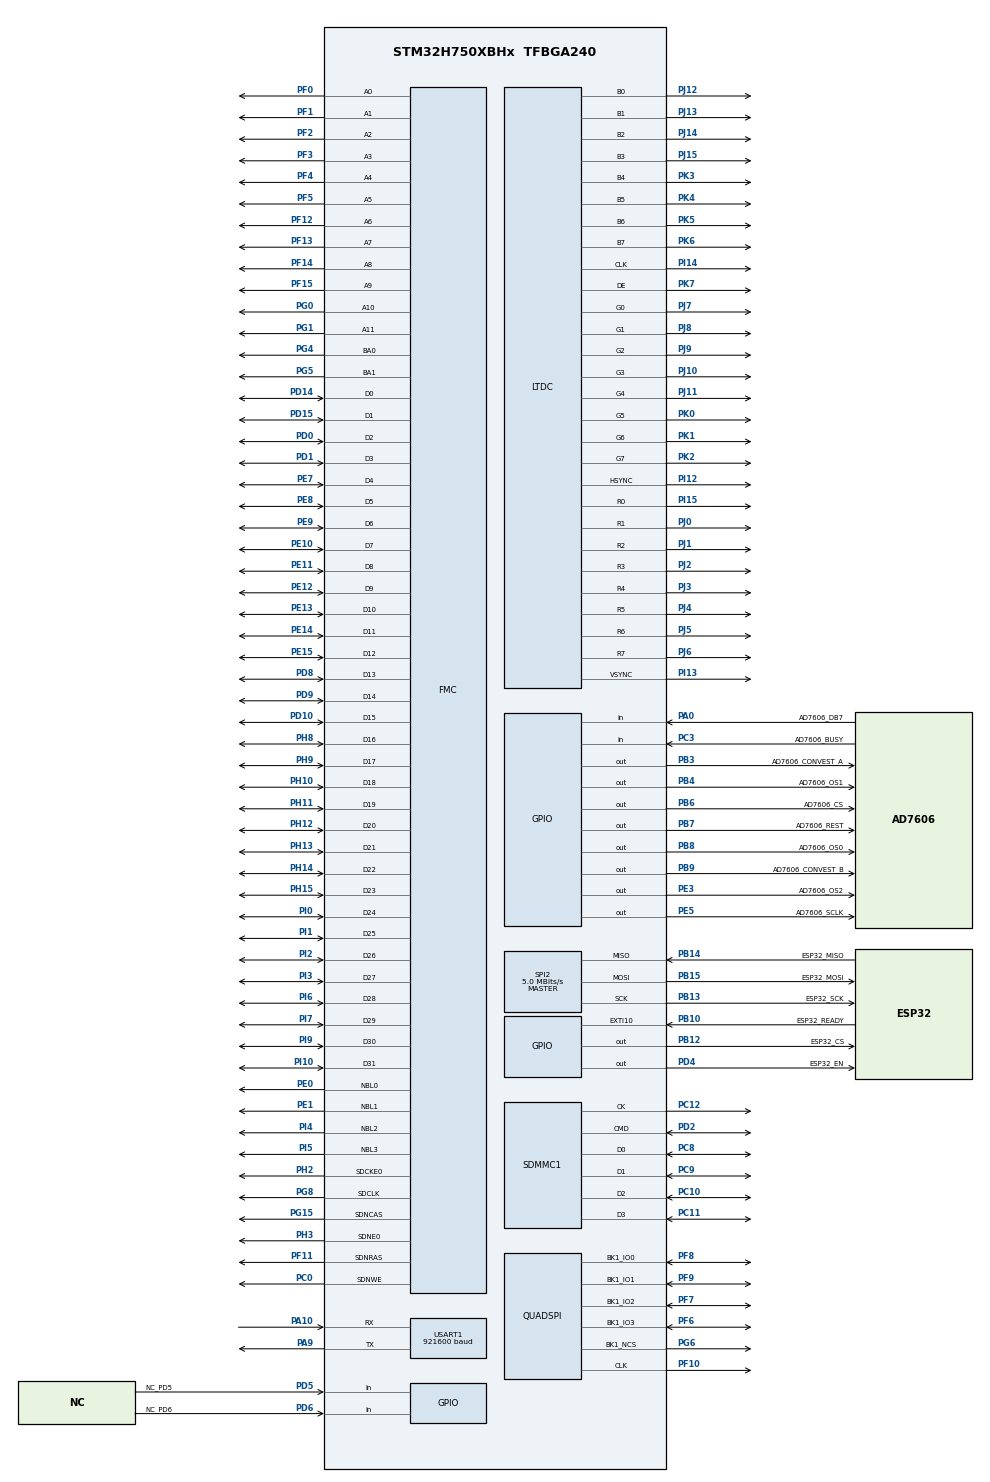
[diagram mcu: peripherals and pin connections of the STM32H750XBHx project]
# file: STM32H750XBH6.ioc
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CORTEX_M7.AccessPermission-Cortex_Memory_Protection_Unit_Region0_Settings=MPU_REGION_FULL_ACCESS
CORTEX_M7.AccessPermission-Cortex_Memory_Protection_Unit_Region1_Settings=MPU_REGION_FULL_ACCESS
CORTEX_M7.BaseAddress-Cortex_Memory_Protection_Unit_Region0_Settings=0xC0000000
CORTEX_M7.BaseAddress-Cortex_Memory_Protection_Unit_Region1_Settings=0x24000000
CORTEX_M7.CPU_DCache=Enabled
CORTEX_M7.CPU_ICache=Enabled
CORTEX_M7.Enable-Cortex_Memory_Protection_Unit_Region0_Settings=MPU_REGION_ENABLE
CORTEX_M7.Enable-Cortex_Memory_Protection_Unit_Region1_Settings=MPU_REGION_ENABLE
CORTEX_M7.IsBufferable-Cortex_Memory_Protection_Unit_Region0_Settings=MPU_ACCESS_NOT_BUFFERABLE
CORTEX_M7.IsBufferable-Cortex_Memory_Protection_Unit_Region1_Settings=MPU_ACCESS_BUFFERABLE
CORTEX_M7.IsCacheable-Cortex_Memory_Protection_Unit_Region0_Settings=MPU_ACCESS_CACHEABLE
CORTEX_M7.IsCacheable-Cortex_Memory_Protection_Unit_Region1_Settings=MPU_ACCESS_CACHEABLE
CORTEX_M7.IsShareable-Cortex_Memory_Protection_Unit_Region1_Settings=MPU_ACCESS_SHAREABLE
CORTEX_M7.MPU_Control=MPU_PRIVILEGED_DEFAULT
CORTEX_M7.Size-Cortex_Memory_Protection_Unit_Region0_Settings=MPU_REGION_SIZE_16MB
CORTEX_M7.Size-Cortex_Memory_Protection_Unit_Region1_Settings=MPU_REGION_SIZE_512KB
CORTEX_M7.TypeExtField-Cortex_Memory_Protection_Unit_Region1_Settings=MPU_TEX_LEVEL1
DMA2D.ColorMode=DMA2D_OUTPUT_RGB565
Dma.Request0=USART1_RX
Dma.Request1=USART1_TX
Dma.Request2=SPI2_RX
Dma.Request3=SPI2_TX
Dma.SPI2_RX.2.Direction=DMA_PERIPH_TO_MEMORY
Dma.SPI2_RX.2.EventEnable=DISABLE
Dma.SPI2_RX.2.FIFOMode=DMA_FIFOMODE_DISABLE
Dma.SPI2_RX.2.Instance=DMA1_Stream4
Dma.SPI2_RX.2.MemDataAlignment=DMA_MDATAALIGN_BYTE
Dma.SPI2_RX.2.MemInc=DMA_MINC_ENABLE
Dma.SPI2_RX.2.Mode=DMA_NORMAL
Dma.SPI2_RX.2.PeriphDataAlignment=DMA_PDATAALIGN_BYTE
Dma.SPI2_RX.2.PeriphInc=DMA_PINC_DISABLE
Dma.SPI2_RX.2.Polarity=HAL_DMAMUX_REQ_GEN_RISING
Dma.SPI2_RX.2.Priority=DMA_PRIORITY_VERY_HIGH
Dma.SPI2_RX.2.RequestNumber=1
Dma.SPI2_RX.2.SignalID=NONE
Dma.SPI2_RX.2.SyncEnable=DISABLE
Dma.SPI2_RX.2.SyncPolarity=HAL_DMAMUX_SYNC_NO_EVENT
Dma.SPI2_RX.2.SyncRequestNumber=1
Dma.SPI2_RX.2.SyncSignalID=NONE
Dma.SPI2_TX.3.Direction=DMA_MEMORY_TO_PERIPH
Dma.SPI2_TX.3.EventEnable=DISABLE
Dma.SPI2_TX.3.FIFOMode=DMA_FIFOMODE_DISABLE
Dma.SPI2_TX.3.Instance=DMA1_Stream5
Dma.SPI2_TX.3.MemDataAlignment=DMA_MDATAALIGN_BYTE
Dma.SPI2_TX.3.MemInc=DMA_MINC_ENABLE
Dma.SPI2_TX.3.Mode=DMA_NORMAL
Dma.SPI2_TX.3.PeriphDataAlignment=DMA_PDATAALIGN_BYTE
Dma.SPI2_TX.3.PeriphInc=DMA_PINC_DISABLE
Dma.SPI2_TX.3.Polarity=HAL_DMAMUX_REQ_GEN_RISING
Dma.SPI2_TX.3.Priority=DMA_PRIORITY_VERY_HIGH
Dma.SPI2_TX.3.RequestNumber=1
Dma.SPI2_TX.3.SignalID=NONE
Dma.SPI2_TX.3.SyncEnable=DISABLE
Dma.SPI2_TX.3.SyncPolarity=HAL_DMAMUX_SYNC_NO_EVENT
Dma.SPI2_TX.3.SyncRequestNumber=1
Dma.SPI2_TX.3.SyncSignalID=NONE
Dma.USART1_RX.0.Direction=DMA_PERIPH_TO_MEMORY
Dma.USART1_RX.0.EventEnable=DISABLE
Dma.USART1_RX.0.FIFOMode=DMA_FIFOMODE_DISABLE
Dma.USART1_RX.0.Instance=DMA1_Stream0
Dma.USART1_RX.0.MemDataAlignment=DMA_MDATAALIGN_BYTE
Dma.USART1_RX.0.MemInc=DMA_MINC_ENABLE
Dma.USART1_RX.0.Mode=DMA_NORMAL
Dma.USART1_RX.0.PeriphDataAlignment=DMA_PDATAALIGN_BYTE
Dma.USART1_RX.0.PeriphInc=DMA_PINC_DISABLE
Dma.USART1_RX.0.Polarity=HAL_DMAMUX_REQ_GEN_RISING
Dma.USART1_RX.0.Priority=DMA_PRIORITY_VERY_HIGH
Dma.USART1_RX.0.RequestNumber=1
Dma.USART1_RX.0.SignalID=NONE
Dma.USART1_RX.0.SyncEnable=DISABLE
Dma.USART1_RX.0.SyncPolarity=HAL_DMAMUX_SYNC_NO_EVENT
Dma.USART1_RX.0.SyncRequestNumber=1
Dma.USART1_RX.0.SyncSignalID=NONE
Dma.USART1_TX.1.Direction=DMA_MEMORY_TO_PERIPH
Dma.USART1_TX.1.EventEnable=DISABLE
Dma.USART1_TX.1.FIFOMode=DMA_FIFOMODE_DISABLE
Dma.USART1_TX.1.Instance=DMA1_Stream1
Dma.USART1_TX.1.MemDataAlignment=DMA_MDATAALIGN_BYTE
Dma.USART1_TX.1.MemInc=DMA_MINC_ENABLE
Dma.USART1_TX.1.Mode=DMA_NORMAL
Dma.USART1_TX.1.PeriphDataAlignment=DMA_PDATAALIGN_BYTE
Dma.USART1_TX.1.PeriphInc=DMA_PINC_DISABLE
Dma.USART1_TX.1.Polarity=HAL_DMAMUX_REQ_GEN_RISING
Dma.USART1_TX.1.Priority=DMA_PRIORITY_VERY_HIGH
Dma.USART1_TX.1.RequestNumber=1
Dma.USART1_TX.1.SignalID=NONE
Dma.USART1_TX.1.SyncEnable=DISABLE
Dma.USART1_TX.1.SyncPolarity=HAL_DMAMUX_SYNC_NO_EVENT
Dma.USART1_TX.1.SyncRequestNumber=1
Dma.USART1_TX.1.SyncSignalID=NONE
FATFS._CODE_PAGE=437
FATFS._FS_LOCK=16
FATFS._USE_LFN=3
FATFS._VOLUMES=2
FMC.CASLatency1=FMC_SDRAM_CAS_LATENCY_3
FMC.ColumnBitsNumber1=FMC_SDRAM_COLUMN_BITS_NUM_8
FMC.ExitSelfRefreshDelay1=7
FMC.LoadToActiveDelay1=2
FMC.RCDDelay1=2
FMC.RPDelay1=2
FMC.RPDelay2=2
FMC.ReadBurst1=FMC_SDRAM_RBURST_ENABLE
FMC.ReadBurst2=FMC_SDRAM_RBURST_ENABLE
FMC.RowCycleDelay1=7
FMC.RowCycleDelay2=7
FMC.SDClockPeriod1=FMC_SDRAM_CLOCK_PERIOD_2
FMC.SDClockPeriod2=FMC_SDRAM_CLOCK_PERIOD_2
FMC.SelfRefreshTime1=4
FMC.WriteRecoveryTime1=3
FREERTOS.Tasks01=LVGL940,24,2048,LVGL_Task,Default,NULL,Dynamic,NULL,NULL;LED,8,128,LED_Task,Default,NULL,Dynamic,NULL,NULL;Main,8,8192,Main_Task,Default,NULL,Dynamic,NULL,NULL;EdgeComm,32,5128,EdgeComm_Task,Default,NULL,Dynamic,NULL,NULL;DSPAlgo,32,3072,DSP_Algorithm_Task,Default,NULL,Dynamic,NULL,NULL;Upload,16,3072,Upload_Task,Default,NULL,Dynamic,NULL,NULL
FREERTOS.configTOTAL_HEAP_SIZE=102400
FREERTOS.configUSE_TICK_HOOK=1
LTDC.ActiveW=800
LTDC.Alpha_L0=255
LTDC.FBStartAdress_L0=0xC0000000
LTDC.HBP=80
LTDC.HFP=200
LTDC.HSync=1
LTDC.ImageHeight_L0=480
LTDC.ImageWidth_L0=800
LTDC.Layers=0
LTDC.PixelFormat_L0=LTDC_PIXEL_FORMAT_RGB565
LTDC.VBP=40
LTDC.VFP=22
LTDC.VSync=1
LTDC.WindowX1_L0=800
LTDC.WindowY1_L0=480
Mcu.Family=STM32H7
Mcu.Name=STM32H750XBHx
Mcu.Package=TFBGA240
Mdma.MDMA_Channel0.Request0=SDMMC1_END_DATA
Mdma.MDMA_Channel0.RequestsNb=1
Mdma.MDMA_Channel0.SDMMC1_END_DATA.0.BlockCount=0
Mdma.MDMA_Channel0.SDMMC1_END_DATA.0.BlockDataLength=0
Mdma.MDMA_Channel0.SDMMC1_END_DATA.0.BufferTransferLength=1
Mdma.MDMA_Channel0.SDMMC1_END_DATA.0.CircularMode=MDMA_LINEAR_LIST
Mdma.MDMA_Channel0.SDMMC1_END_DATA.0.DataAlignment=MDMA_DATAALIGN_PACKENABLE
Mdma.MDMA_Channel0.SDMMC1_END_DATA.0.DestBlockAddressOffset=0
Mdma.MDMA_Channel0.SDMMC1_END_DATA.0.DestBurst=MDMA_DEST_BURST_SINGLE
Mdma.MDMA_Channel0.SDMMC1_END_DATA.0.DestDataSize=MDMA_DEST_DATASIZE_BYTE
Mdma.MDMA_Channel0.SDMMC1_END_DATA.0.DestinationInc=MDMA_DEST_INC_BYTE
Mdma.MDMA_Channel0.SDMMC1_END_DATA.0.DstAddress=0
Mdma.MDMA_Channel0.SDMMC1_END_DATA.0.Endianness=MDMA_LITTLE_ENDIANNESS_PRESERVE
Mdma.MDMA_Channel0.SDMMC1_END_DATA.0.Instance=MDMA_Channel0
Mdma.MDMA_Channel0.SDMMC1_END_DATA.0.MaskAddress=0
Mdma.MDMA_Channel0.SDMMC1_END_DATA.0.MaskData=0
Mdma.MDMA_Channel0.SDMMC1_END_DATA.0.Priority=MDMA_PRIORITY_LOW
Mdma.MDMA_Channel0.SDMMC1_END_DATA.0.Rank=First
Mdma.MDMA_Channel0.SDMMC1_END_DATA.0.SourceBlockAddressOffset=0
Mdma.MDMA_Channel0.SDMMC1_END_DATA.0.SourceBurst=MDMA_SOURCE_BURST_SINGLE
Mdma.MDMA_Channel0.SDMMC1_END_DATA.0.SourceDataSize=MDMA_SRC_DATASIZE_BYTE
Mdma.MDMA_Channel0.SDMMC1_END_DATA.0.SourceInc=MDMA_SRC_INC_BYTE
Mdma.MDMA_Channel0.SDMMC1_END_DATA.0.SrcAddress=0
Mdma.MDMA_Channel0.SDMMC1_END_DATA.0.TransferTriggerMode=MDMA_BUFFER_TRANSFER
Mdma.MDMA_Channel1.QUADSPI_FIFO_TH.0.BlockCount=0
Mdma.MDMA_Channel1.QUADSPI_FIFO_TH.0.BlockDataLength=0
Mdma.MDMA_Channel1.QUADSPI_FIFO_TH.0.BufferTransferLength=128
Mdma.MDMA_Channel1.QUADSPI_FIFO_TH.0.CircularMode=MDMA_LINEAR_LIST
Mdma.MDMA_Channel1.QUADSPI_FIFO_TH.0.DataAlignment=MDMA_DATAALIGN_PACKENABLE
Mdma.MDMA_Channel1.QUADSPI_FIFO_TH.0.DestBlockAddressOffset=0
Mdma.MDMA_Channel1.QUADSPI_FIFO_TH.0.DestBurst=MDMA_DEST_BURST_SINGLE
Mdma.MDMA_Channel1.QUADSPI_FIFO_TH.0.DestDataSize=MDMA_DEST_DATASIZE_WORD
Mdma.MDMA_Channel1.QUADSPI_FIFO_TH.0.DestinationInc=MDMA_DEST_INC_DISABLE
Mdma.MDMA_Channel1.QUADSPI_FIFO_TH.0.DstAddress=0
Mdma.MDMA_Channel1.QUADSPI_FIFO_TH.0.Endianness=MDMA_LITTLE_ENDIANNESS_PRESERVE
Mdma.MDMA_Channel1.QUADSPI_FIFO_TH.0.Instance=MDMA_Channel1
Mdma.MDMA_Channel1.QUADSPI_FIFO_TH.0.MaskAddress=0
Mdma.MDMA_Channel1.QUADSPI_FIFO_TH.0.MaskData=0
Mdma.MDMA_Channel1.QUADSPI_FIFO_TH.0.Priority=MDMA_PRIORITY_VERY_HIGH
Mdma.MDMA_Channel1.QUADSPI_FIFO_TH.0.Rank=First
Mdma.MDMA_Channel1.QUADSPI_FIFO_TH.0.SourceBlockAddressOffset=0
Mdma.MDMA_Channel1.QUADSPI_FIFO_TH.0.SourceBurst=MDMA_SOURCE_BURST_SINGLE
Mdma.MDMA_Channel1.QUADSPI_FIFO_TH.0.SourceDataSize=MDMA_SRC_DATASIZE_WORD
Mdma.MDMA_Channel1.QUADSPI_FIFO_TH.0.SourceInc=MDMA_SRC_INC_WORD
Mdma.MDMA_Channel1.QUADSPI_FIFO_TH.0.SrcAddress=0
Mdma.MDMA_Channel1.QUADSPI_FIFO_TH.0.TransferTriggerMode=MDMA_BUFFER_TRANSFER
Mdma.MDMA_Channel1.Request0=QUADSPI_FIFO_TH
Mdma.MDMA_Channel1.RequestsNb=1
Mdma.RequestSet0=MDMA_Channel0
Mdma.RequestSet1=MDMA_Channel1
Mdma.RequestSetsNb=2
NVIC.DMA1_Stream0_IRQn=true\:5\:0\:false\:false\:true\:true\:false\:true\:true
NVIC.DMA1_Stream1_IRQn=true\:5\:0\:false\:false\:true\:true\:false\:true\:true
NVIC.DMA1_Stream4_IRQn=true\:5\:0\:false\:false\:true\:true\:false\:true\:true
NVIC.DMA1_Stream5_IRQn=true\:5\:0\:false\:false\:true\:true\:false\:true\:true
NVIC.EXTI15_10_IRQn=true\:5\:0\:false\:false\:true\:true\:true\:true\:true
NVIC.LTDC_IRQn=true\:5\:0\:false\:false\:true\:true\:true\:true\:true
NVIC.MDMA_IRQn=true\:6\:0\:true\:false\:true\:true\:false\:true\:true
NVIC.PriorityGroup=NVIC_PRIORITYGROUP_4
NVIC.QUADSPI_IRQn=true\:5\:0\:false\:false\:true\:true\:true\:true\:true
NVIC.SDMMC1_IRQn=true\:6\:0\:true\:false\:true\:true\:true\:true\:true
NVIC.SPI2_IRQn=true\:5\:0\:false\:false\:true\:true\:false\:true\:true
NVIC.TIM17_IRQn=true\:15\:0\:false\:false\:true\:false\:false\:true\:true
NVIC.TIM2_IRQn=true\:5\:0\:false\:false\:true\:true\:true\:true\:true
NVIC.TIM3_IRQn=true\:5\:0\:false\:false\:true\:true\:true\:true\:true
NVIC.TimeBase=TIM17_IRQn
NVIC.TimeBaseIP=TIM17
NVIC.USART1_IRQn=true\:5\:0\:false\:false\:true\:true\:true\:true\:true
PA0.GPIO_Label=AD7606_DB7
PA0.Signal=GPIO_Input
PA10.GPIO_Speed=GPIO_SPEED_FREQ_VERY_HIGH
PA10.Mode=Asynchronous
PA10.Signal=USART1_RX
PA13\ (JTMS/SWDIO).Mode=Serial_Wire
PA13\ (JTMS/SWDIO).Signal=DEBUG_JTMS-SWDIO
PA14\ (JTCK/SWCLK).Mode=Serial_Wire
PA14\ (JTCK/SWCLK).Signal=DEBUG_JTCK-SWCLK
PA9.GPIO_Speed=GPIO_SPEED_FREQ_VERY_HIGH
PA9.Mode=Asynchronous
PA9.Signal=USART1_TX
PB10.GPIO_Label=ESP32_READY
PB10.GPIO_PuPd=GPIO_PULLDOWN
PB10.Signal=GPXTI10
PB12.GPIO_Label=ESP32_CS
PB12.GPIO_Speed=GPIO_SPEED_FREQ_VERY_HIGH
PB12.PinState=GPIO_PIN_SET
PB12.Signal=GPIO_Output
PB13.GPIO_Label=ESP32_SCK
PB13.GPIO_Speed=GPIO_SPEED_FREQ_VERY_HIGH
PB13.Mode=Full_Duplex_Master
PB13.Signal=SPI2_SCK
PB14.GPIO_Label=ESP32_MISO
PB14.GPIO_Speed=GPIO_SPEED_FREQ_VERY_HIGH
PB14.Mode=Full_Duplex_Master
PB14.Signal=SPI2_MISO
PB15.GPIO_Label=ESP32_MOSI
PB15.GPIO_Speed=GPIO_SPEED_FREQ_VERY_HIGH
PB15.Mode=Full_Duplex_Master
PB15.Signal=SPI2_MOSI
PB3\ (JTDO/TRACESWO).GPIO_Label=AD7606_CONVEST_A
PB3\ (JTDO/TRACESWO).GPIO_Speed=GPIO_SPEED_FREQ_VERY_HIGH
PB3\ (JTDO/TRACESWO).Signal=GPIO_Output
PB4\ (NJTRST).GPIO_Label=AD7606_OS1
PB4\ (NJTRST).GPIO_Speed=GPIO_SPEED_FREQ_VERY_HIGH
PB4\ (NJTRST).Signal=GPIO_Output
PB6.GPIO_Label=AD7606_CS
PB6.GPIO_Speed=GPIO_SPEED_FREQ_VERY_HIGH
PB6.Signal=GPIO_Output
PB7.GPIO_Label=AD7606_REST
PB7.GPIO_Speed=GPIO_SPEED_FREQ_VERY_HIGH
PB7.Signal=GPIO_Output
PB8.GPIO_Label=AD7606_OS0
PB8.GPIO_Speed=GPIO_SPEED_FREQ_VERY_HIGH
PB8.Signal=GPIO_Output
PB9.GPIO_Label=AD7606_CONVEST_B
PB9.GPIO_Speed=GPIO_SPEED_FREQ_VERY_HIGH
PB9.Signal=GPIO_Output
PC0.Signal=FMC_SDNWE
PC10.GPIO_PuPd=GPIO_NOPULL
PC10.Mode=SD_4_bits_Wide_bus
PC10.Signal=SDMMC1_D2
PC11.GPIO_PuPd=GPIO_NOPULL
PC11.Mode=SD_4_bits_Wide_bus
PC11.Signal=SDMMC1_D3
PC12.GPIO_PuPd=GPIO_NOPULL
PC12.Mode=SD_4_bits_Wide_bus
PC12.Signal=SDMMC1_CK
PC14-OSC32_IN\ (OSC32_IN).Mode=LSE-External-Oscillator
PC14-OSC32_IN\ (OSC32_IN).Signal=RCC_OSC32_IN
PC15-OSC32_OUT\ (OSC32_OUT).Mode=LSE-External-Oscillator
PC15-OSC32_OUT\ (OSC32_OUT).Signal=RCC_OSC32_OUT
PC3.GPIO_Label=AD7606_BUSY
PC3.Signal=GPIO_Input
PC8.GPIO_PuPd=GPIO_NOPULL
PC8.Mode=SD_4_bits_Wide_bus
PC8.Signal=SDMMC1_D0
PC9.GPIO_PuPd=GPIO_NOPULL
PC9.Mode=SD_4_bits_Wide_bus
PC9.Signal=SDMMC1_D1
PD0.Signal=FMC_D2_DA2
PD1.Signal=FMC_D3_DA3
PD10.Signal=FMC_D15_DA15
PD14.Signal=FMC_D0_DA0
PD15.Signal=FMC_D1_DA1
PD2.GPIO_PuPd=GPIO_NOPULL
PD2.Mode=SD_4_bits_Wide_bus
PD2.Signal=SDMMC1_CMD
PD4.GPIO_Label=ESP32_EN
PD4.GPIO_ModeDefaultOutputPP=GPIO_MODE_OUTPUT_OD
PD4.GPIO_PuPd=GPIO_NOPULL
PD4.GPIO_Speed=GPIO_SPEED_FREQ_VERY_HIGH
PD4.PinState=GPIO_PIN_SET
PD4.Signal=GPIO_Output
PD5.GPIO_Label=NC_PD5
PD5.Signal=GPIO_Input
PD6.GPIO_Label=NC_PD6
PD6.Signal=GPIO_Input
PD8.Signal=FMC_D13_DA13
PD9.Signal=FMC_D14_DA14
PE0.Signal=FMC_NBL0
PE1.Signal=FMC_NBL1
PE10.Signal=FMC_D7_DA7
PE11.Signal=FMC_D8_DA8
PE12.Signal=FMC_D9_DA9
PE13.Signal=FMC_D10_DA10
PE14.Signal=FMC_D11_DA11
PE15.Signal=FMC_D12_DA12
PE3.GPIO_Label=AD7606_OS2
PE3.GPIO_Speed=GPIO_SPEED_FREQ_VERY_HIGH
PE3.Signal=GPIO_Output
PE5.GPIO_Label=AD7606_SCLK
PE5.GPIO_Speed=GPIO_SPEED_FREQ_VERY_HIGH
PE5.Signal=GPIO_Output
PE7.Signal=FMC_D4_DA4
PE8.Signal=FMC_D5_DA5
PE9.Signal=FMC_D6_DA6
PF0.Signal=FMC_A0
PF1.Signal=FMC_A1
PF10.GPIO_Speed=GPIO_SPEED_FREQ_VERY_HIGH
PF10.Mode=Single Bank 1
PF10.Signal=QUADSPI_CLK
PF11.Signal=FMC_SDNRAS
PF12.Signal=FMC_A6
PF13.Signal=FMC_A7
PF14.Signal=FMC_A8
PF15.Signal=FMC_A9
PF2.Signal=FMC_A2
PF3.Signal=FMC_A3
PF4.Signal=FMC_A4
PF5.Signal=FMC_A5
PF6.GPIO_Speed=GPIO_SPEED_FREQ_VERY_HIGH
PF6.Mode=Single Bank 1
PF6.Signal=QUADSPI_BK1_IO3
PF7.GPIO_Speed=GPIO_SPEED_FREQ_VERY_HIGH
PF7.Mode=Single Bank 1
PF7.Signal=QUADSPI_BK1_IO2
PF8.GPIO_Speed=GPIO_SPEED_FREQ_VERY_HIGH
PF8.Mode=Single Bank 1
PF8.Signal=QUADSPI_BK1_IO0
PF9.GPIO_Speed=GPIO_SPEED_FREQ_VERY_HIGH
PF9.Mode=Single Bank 1
PF9.Signal=QUADSPI_BK1_IO1
PG0.Signal=FMC_A10
PG1.Signal=FMC_A11
PG15.Signal=FMC_SDNCAS
PG4.Signal=FMC_A14_BA0
PG5.Signal=FMC_A15_BA1
PG6.GPIO_Speed=GPIO_SPEED_FREQ_VERY_HIGH
PG6.Mode=Single Bank 1
PG6.Signal=QUADSPI_BK1_NCS
PG8.Signal=FMC_SDCLK
PH0-OSC_IN\ (PH0).Mode=HSE-External-Oscillator
PH0-OSC_IN\ (PH0).Signal=RCC_OSC_IN
PH1-OSC_OUT\ (PH1).Mode=HSE-External-Oscillator
PH1-OSC_OUT\ (PH1).Signal=RCC_OSC_OUT
PH10.Signal=FMC_D18
PH11.Signal=FMC_D19
PH12.Signal=FMC_D20
PH13.Signal=FMC_D21
PH14.Signal=FMC_D22
PH15.Signal=FMC_D23
PH2.Mode=SdramChipSelect1_1
PH2.Signal=FMC_SDCKE0
PH3.Mode=SdramChipSelect1_1
PH3.Signal=FMC_SDNE0
PH8.Signal=FMC_D16
PH9.Signal=FMC_D17
PI0.Signal=FMC_D24
PI1.Signal=FMC_D25
PI10.Signal=FMC_D31
PI12.GPIO_Speed=GPIO_SPEED_FREQ_VERY_HIGH
PI12.Mode=RGB888
PI12.Signal=LTDC_HSYNC
PI13.GPIO_Speed=GPIO_SPEED_FREQ_VERY_HIGH
PI13.Mode=RGB888
PI13.Signal=LTDC_VSYNC
PI14.GPIO_Speed=GPIO_SPEED_FREQ_VERY_HIGH
PI14.Mode=RGB888
PI14.Signal=LTDC_CLK
PI15.GPIO_Speed=GPIO_SPEED_FREQ_VERY_HIGH
PI15.Mode=RGB888
PI15.Signal=LTDC_R0
PI2.Signal=FMC_D26
PI3.Signal=FMC_D27
PI4.Signal=FMC_NBL2
PI5.Signal=FMC_NBL3
PI6.Signal=FMC_D28
PI7.Signal=FMC_D29
PI9.Signal=FMC_D30
PJ0.GPIO_Speed=GPIO_SPEED_FREQ_VERY_HIGH
PJ0.Mode=RGB888
PJ0.Signal=LTDC_R1
PJ1.GPIO_Speed=GPIO_SPEED_FREQ_VERY_HIGH
PJ1.Mode=RGB888
PJ1.Signal=LTDC_R2
PJ10.GPIO_Speed=GPIO_SPEED_FREQ_VERY_HIGH
PJ10.Mode=RGB888
PJ10.Signal=LTDC_G3
PJ11.GPIO_Speed=GPIO_SPEED_FREQ_VERY_HIGH
PJ11.Mode=RGB888
PJ11.Signal=LTDC_G4
PJ12.GPIO_Speed=GPIO_SPEED_FREQ_VERY_HIGH
PJ12.Mode=RGB888
PJ12.Signal=LTDC_B0
PJ13.GPIO_Speed=GPIO_SPEED_FREQ_VERY_HIGH
PJ13.Mode=RGB888
PJ13.Signal=LTDC_B1
PJ14.GPIO_Speed=GPIO_SPEED_FREQ_VERY_HIGH
PJ14.Mode=RGB888
PJ14.Signal=LTDC_B2
PJ15.GPIO_Speed=GPIO_SPEED_FREQ_VERY_HIGH
PJ15.Mode=RGB888
PJ15.Signal=LTDC_B3
PJ2.GPIO_Speed=GPIO_SPEED_FREQ_VERY_HIGH
PJ2.Mode=RGB888
PJ2.Signal=LTDC_R3
PJ3.GPIO_Speed=GPIO_SPEED_FREQ_VERY_HIGH
PJ3.Mode=RGB888
PJ3.Signal=LTDC_R4
PJ4.GPIO_Speed=GPIO_SPEED_FREQ_VERY_HIGH
PJ4.Mode=RGB888
PJ4.Signal=LTDC_R5
PJ5.GPIO_Speed=GPIO_SPEED_FREQ_VERY_HIGH
PJ5.Mode=RGB888
PJ5.Signal=LTDC_R6
PJ6.GPIO_Speed=GPIO_SPEED_FREQ_VERY_HIGH
PJ6.Mode=RGB888
PJ6.Signal=LTDC_R7
PJ7.GPIO_Speed=GPIO_SPEED_FREQ_VERY_HIGH
PJ7.Mode=RGB888
PJ7.Signal=LTDC_G0
PJ8.GPIO_Speed=GPIO_SPEED_FREQ_VERY_HIGH
PJ8.Mode=RGB888
PJ8.Signal=LTDC_G1
PJ9.GPIO_Speed=GPIO_SPEED_FREQ_VERY_HIGH
PJ9.Mode=RGB888
PJ9.Signal=LTDC_G2
PK0.GPIO_Speed=GPIO_SPEED_FREQ_VERY_HIGH
PK0.Mode=RGB888
PK0.Signal=LTDC_G5
PK1.GPIO_Speed=GPIO_SPEED_FREQ_VERY_HIGH
PK1.Mode=RGB888
PK1.Signal=LTDC_G6
PK2.GPIO_Speed=GPIO_SPEED_FREQ_VERY_HIGH
PK2.Mode=RGB888
PK2.Signal=LTDC_G7
PK3.GPIO_Speed=GPIO_SPEED_FREQ_VERY_HIGH
PK3.Mode=RGB888
PK3.Signal=LTDC_B4
PK4.GPIO_Speed=GPIO_SPEED_FREQ_VERY_HIGH
PK4.Mode=RGB888
PK4.Signal=LTDC_B5
PK5.GPIO_Speed=GPIO_SPEED_FREQ_VERY_HIGH
PK5.Mode=RGB888
PK5.Signal=LTDC_B6
PK6.GPIO_Speed=GPIO_SPEED_FREQ_VERY_HIGH
PK6.Mode=RGB888
PK6.Signal=LTDC_B7
PK7.GPIO_Speed=GPIO_SPEED_FREQ_VERY_HIGH
PK7.Mode=RGB888
PK7.Signal=LTDC_DE
ProjectManager.HeapSize=0x2000
ProjectManager.StackSize=0x2000
ProjectManager.TargetToolchain=MDK-ARM V5.32
QUADSPI.ClockMode=QSPI_CLOCK_MODE_3
QUADSPI.ClockPrescaler=1
QUADSPI.FifoThreshold=32
QUADSPI.FlashSize=24
QUADSPI.SampleShifting=QSPI_SAMPLE_SHIFTING_HALFCYCLE
RCC.ADCFreq_Value=160000000
RCC.APB1Freq_Value=120000000
RCC.APB2Freq_Value=120000000
RCC.APB3Freq_Value=120000000
RCC.APB4Freq_Value=120000000
RCC.CortexFreq_Value=480000000
RCC.D1PPRE=RCC_APB3_DIV2
RCC.D2PPRE1=RCC_APB1_DIV2
RCC.D2PPRE2=RCC_APB2_DIV2
RCC.D3PPRE=RCC_APB4_DIV2
RCC.DIVM1=5
RCC.DIVM2=5
RCC.DIVM3=1
RCC.DIVN1=192
RCC.DIVN2=160
RCC.DIVN3=6
RCC.DIVP2=5
RCC.DIVQ1=4
RCC.DIVR3=3
RCC.HCLKFreq_Value=240000000
RCC.HPRE=RCC_HCLK_DIV2
RCC.HSE_VALUE=25000000
RCC.PLL2FRACN=0
RCC.PLL3FRACN=0
RCC.PLLFRACN=0
RCC.PLLSourceVirtual=RCC_PLLSOURCE_HSE
RCC.RTCClockSelection=RCC_RTCCLKSOURCE_LSE
RCC.SPI123CLockSelection=RCC_SPI123CLKSOURCE_PLL2
RCC.SYSCLKFreq_VALUE=480000000
RCC.SYSCLKSource=RCC_SYSCLKSOURCE_PLLCLK
RCC.USBFreq_Value=240000000
SDMMC1.ClockDiv=0
SH.FMC_A0.0=FMC_A0,12b-sda1
SH.FMC_A1.0=FMC_A1,12b-sda1
SH.FMC_A10.0=FMC_A10,12b-sda1
SH.FMC_A11.0=FMC_A11,12b-sda1
SH.FMC_A14_BA0.0=FMC_BA0,FourSdramBanks1
SH.FMC_A15_BA1.0=FMC_BA1,FourSdramBanks1
SH.FMC_A2.0=FMC_A2,12b-sda1
SH.FMC_A3.0=FMC_A3,12b-sda1
SH.FMC_A4.0=FMC_A4,12b-sda1
SH.FMC_A5.0=FMC_A5,12b-sda1
SH.FMC_A6.0=FMC_A6,12b-sda1
SH.FMC_A7.0=FMC_A7,12b-sda1
SH.FMC_A8.0=FMC_A8,12b-sda1
SH.FMC_A9.0=FMC_A9,12b-sda1
SH.FMC_D0_DA0.0=FMC_D0,sd-32b-d1
SH.FMC_D10_DA10.0=FMC_D10,sd-32b-d1
SH.FMC_D11_DA11.0=FMC_D11,sd-32b-d1
SH.FMC_D12_DA12.0=FMC_D12,sd-32b-d1
SH.FMC_D13_DA13.0=FMC_D13,sd-32b-d1
SH.FMC_D14_DA14.0=FMC_D14,sd-32b-d1
SH.FMC_D15_DA15.0=FMC_D15,sd-32b-d1
SH.FMC_D16.0=FMC_D16,sd-32b-d1
SH.FMC_D17.0=FMC_D17,sd-32b-d1
SH.FMC_D18.0=FMC_D18,sd-32b-d1
SH.FMC_D19.0=FMC_D19,sd-32b-d1
SH.FMC_D1_DA1.0=FMC_D1,sd-32b-d1
SH.FMC_D20.0=FMC_D20,sd-32b-d1
SH.FMC_D21.0=FMC_D21,sd-32b-d1
SH.FMC_D22.0=FMC_D22,sd-32b-d1
SH.FMC_D23.0=FMC_D23,sd-32b-d1
SH.FMC_D24.0=FMC_D24,sd-32b-d1
SH.FMC_D25.0=FMC_D25,sd-32b-d1
SH.FMC_D26.0=FMC_D26,sd-32b-d1
SH.FMC_D27.0=FMC_D27,sd-32b-d1
SH.FMC_D28.0=FMC_D28,sd-32b-d1
SH.FMC_D29.0=FMC_D29,sd-32b-d1
SH.FMC_D2_DA2.0=FMC_D2,sd-32b-d1
SH.FMC_D30.0=FMC_D30,sd-32b-d1
SH.FMC_D31.0=FMC_D31,sd-32b-d1
SH.FMC_D3_DA3.0=FMC_D3,sd-32b-d1
SH.FMC_D4_DA4.0=FMC_D4,sd-32b-d1
SH.FMC_D5_DA5.0=FMC_D5,sd-32b-d1
SH.FMC_D6_DA6.0=FMC_D6,sd-32b-d1
SH.FMC_D7_DA7.0=FMC_D7,sd-32b-d1
SH.FMC_D8_DA8.0=FMC_D8,sd-32b-d1
SH.FMC_D9_DA9.0=FMC_D9,sd-32b-d1
SH.FMC_NBL0.0=FMC_NBL0,Sd4ByteEnable1
SH.FMC_NBL1.0=FMC_NBL1,Sd4ByteEnable1
SH.FMC_NBL2.0=FMC_NBL2,Sd4ByteEnable1
SH.FMC_NBL3.0=FMC_NBL3,Sd4ByteEnable1
SH.FMC_SDCLK.0=FMC_SDCLK,12b-sda1
SH.FMC_SDNCAS.0=FMC_SDNCAS,12b-sda1
SH.FMC_SDNRAS.0=FMC_SDNRAS,12b-sda1
SH.FMC_SDNWE.0=FMC_SDNWE,12b-sda1
SPI2.BaudRatePrescaler=SPI_BAUDRATEPRESCALER_32
SPI2.CalculateBaudRate=5.0 MBits/s
SPI2.DataSize=SPI_DATASIZE_8BIT
SPI2.Direction=SPI_DIRECTION_2LINES
SPI2.Mode=SPI_MODE_MASTER
SPI2.VirtualType=VM_MASTER
STMicroelectronics.X-CUBE-AI.10.2.0.ActivationBufferSizeList=304028
STMicroelectronics.X-CUBE-AI.10.2.0.ActivationBuffers=pool0
STMicroelectronics.X-CUBE-AI.10.2.0.ActivationNames=pool0
STMicroelectronics.X-CUBE-AI.10.2.0.ActivationSizes=AI_NETWORK_DATA_ACTIVATION_1_SIZE
STMicroelectronics.X-CUBE-AI.10.2.0.HeapSize=0x2000
STMicroelectronics.X-CUBE-AI.10.2.0.InternalRamActivationBufferMaxSize=AI_NETWORK_DATA_ACTIVATIONS_SIZE
STMicroelectronics.X-CUBE-AI.10.2.0.ExternalRamActivationBufferMaxSize=524288
STMicroelectronics.X-CUBE-AI.10.2.0.ExternalRamActivationBufferStartAddr=0xC0600000
STMicroelectronics.X-CUBE-AI.10.2.0.LatestDirectoryUsed-dc39c142f5a094e7d1a7c571dd2a85498169e191eaba9ff1da70ae515eace6f7=C\:\\Users\\pengjianzhong\\Desktop\\MY_Project\\EdgeWind_AI_Training\\stm32_deploy_packages\\dataset_v68_wind_sensor_public_fused_single_v6_single7_20260616_031448\\model
STMicroelectronics.X-CUBE-AI.10.2.0.MaximumNumberOfInputLayer=3
STMicroelectronics.X-CUBE-AI.10.2.0.MaximumNumberOfOutputLayer=1
STMicroelectronics.X-CUBE-AI.10.2.0.MaximumSizeOfInputLayer=1,1,1
STMicroelectronics.X-CUBE-AI.10.2.0.MaximumSizeOfOutputLayer=1
STMicroelectronics.X-CUBE-AI.10.2.0.ModelActualCompression-dc39c142f5a094e7d1a7c571dd2a85498169e191eaba9ff1da70ae515eace6f7=0.0
STMicroelectronics.X-CUBE-AI.10.2.0.ModelCompression-dc39c142f5a094e7d1a7c571dd2a85498169e191eaba9ff1da70ae515eace6f7=None
STMicroelectronics.X-CUBE-AI.10.2.0.ModelFlashOccupation-dc39c142f5a094e7d1a7c571dd2a85498169e191eaba9ff1da70ae515eace6f7=262716
STMicroelectronics.X-CUBE-AI.10.2.0.ModelHashList=dc39c142f5a094e7d1a7c571dd2a85498169e191eaba9ff1da70ae515eace6f7
STMicroelectronics.X-CUBE-AI.10.2.0.ModelKind-dc39c142f5a094e7d1a7c571dd2a85498169e191eaba9ff1da70ae515eace6f7=TFLITE
STMicroelectronics.X-CUBE-AI.10.2.0.ModelMacc-dc39c142f5a094e7d1a7c571dd2a85498169e191eaba9ff1da70ae515eace6f7=6216960
STMicroelectronics.X-CUBE-AI.10.2.0.ModelName-dc39c142f5a094e7d1a7c571dd2a85498169e191eaba9ff1da70ae515eace6f7=network
STMicroelectronics.X-CUBE-AI.10.2.0.ModelNameList=network
STMicroelectronics.X-CUBE-AI.10.2.0.ModelRamOccupation-dc39c142f5a094e7d1a7c571dd2a85498169e191eaba9ff1da70ae515eace6f7=304028
STMicroelectronics.X-CUBE-AI.10.2.0.ModelStructureFile-dc39c142f5a094e7d1a7c571dd2a85498169e191eaba9ff1da70ae515eace6f7=C\:\\Users\\pengjianzhong\\Desktop\\MY_Project\\EdgeWind_AI_Training\\stm32_deploy_packages\\dataset_v68_wind_sensor_public_fused_single_v6_single7_20260616_031448\\model\\model_float32.tflite
STMicroelectronics.X-CUBE-AI.10.2.0.ModelType-dc39c142f5a094e7d1a7c571dd2a85498169e191eaba9ff1da70ae515eace6f7=STM32Cube.AI MCU runtime
STMicroelectronics.X-CUBE-AI.10.2.0.ReadyForCodeGeneration=true
STMicroelectronics.X-CUBE-AI.10.2.0.StackSize=0x2000
STMicroelectronics.X-CUBE-AI.10.2.0.WorkingBufferStartAddrList=0xC0600000
STMicroelectronics.X-CUBE-AI.10.2.0.XAaCUBEAaAICcArtificialOoIntelligenceJjCore=true
STMicroelectronics.X-CUBE-AI.10.2.0.copyWeightToRam=false
STMicroelectronics.X-CUBE-AI.10.2.0.copyWeightToRam-dc39c142f5a094e7d1a7c571dd2a85498169e191eaba9ff1da70ae515eace6f7=false
STMicroelectronics.X-CUBE-AI.10.2.0.customLayerConfigEnabled=false
STMicroelectronics.X-CUBE-AI.10.2.0.customLayerConfigEnabled-dc39c142f5a094e7d1a7c571dd2a85498169e191eaba9ff1da70ae515eace6f7=false
STMicroelectronics.X-CUBE-AI.10.2.0.noOnnxIoTranspose=false
STMicroelectronics.X-CUBE-AI.10.2.0.noOnnxIoTranspose-dc39c142f5a094e7d1a7c571dd2a85498169e191eaba9ff1da70ae515eace6f7=false
STMicroelectronics.X-CUBE-AI.10.2.0.useInputAllocation=true
STMicroelectronics.X-CUBE-AI.10.2.0.useInputAllocation-dc39c142f5a094e7d1a7c571dd2a85498169e191eaba9ff1da70ae515eace6f7=true
STMicroelectronics.X-CUBE-AI.10.2.0.useOutputAllocation=true
STMicroelectronics.X-CUBE-AI.10.2.0.useOutputAllocation-dc39c142f5a094e7d1a7c571dd2a85498169e191eaba9ff1da70ae515eace6f7=true
TIM16.Prescaler=240-1
TIM2.Period=75-1
TIM2.Prescaler=125-1
TIM3.Period=10000-1
TIM3.Prescaler=24000-1
USART1.BaudRate=921600
USART1.VirtualMode-Asynchronous=VM_ASYNC
VP_DMA2D_VS_DMA2D.Mode=DMA2D_Activate
VP_FATFS_VS_SDIO.Mode=SDIO
VP_FREERTOS_VS_CMSIS_V2.Mode=CMSIS_V2
VP_MEMORYMAP_VS_MEMORYMAP.Mode=CurAppReg
VP_RTC_VS_RTC_Activate.Mode=RTC_Enabled
VP_RTC_VS_RTC_Calendar.Mode=RTC_Calendar
VP_STMicroelectronics.X-CUBE-AI_VS_ArtificialOoIntelligenceJjXAaCUBEAaAI_10.2.0.Mode=ArtificialOoIntelligenceJjXAaCUBEAaAI
VP_SYS_VS_tim17.Mode=TIM17
VP_TIM16_VS_ClockSourceINT.Mode=Enable_Timer
VP_TIM2_VS_ClockSourceINT.Mode=Internal
VP_TIM3_VS_ClockSourceINT.Mode=Internal
board=custom

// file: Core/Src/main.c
/* USER CODE BEGIN Header */
/**
 ******************************************************************************
 * @file           : main.c
 * @brief          : Main program body
 ******************************************************************************
 * @attention
 *
 * Copyright (c) 2024 STMicroelectronics.
 * All rights reserved.
 *
 * This software is licensed under terms that can be found in the LICENSE file
 * in the root directory of this software component.
 * If no LICENSE file comes with this software, it is provided AS-IS.
 *
 ******************************************************************************
 */
/* USER CODE END Header */
#include "main.h"
#include "cmsis_os.h"
#include "dma.h"
#include "dma2d.h"
#include "fatfs.h"
#include "ltdc.h"
#include "mdma.h"
#include "quadspi.h"
#include "rtc.h"
#include "sdmmc.h"
#include "spi.h"
#include "tim.h"
#include "usart.h"
#include "gpio.h"
#include "fmc.h"

/* USER CODE BEGIN Includes */
#include "led.h"
#include "sdram.h"
#include "lcd_rgb.h"
#include "touch_800x480.h"
#include "lvgl.h"
#include "lv_port_disp.h"
#include "lv_port_indev.h"
// Demo 已移除，使用自定义 EdgeWind UI

#include <string.h>
#include "arm_math.h"
#include <stdio.h>
#include <stdarg.h>
#include "arm_const_structs.h"

#include <stdio.h>

#include "edge_comm.h"
#include "SPI_AD7606.h"
#include "ad_acq_buffers.h"

/* USER CODE END Includes */

/* USER CODE BEGIN PV */
osMutexId_t mutex_id; //

const osMutexAttr_t Thread_Mutex_attr = {
    //
    "myThreadMutex",    // human readable mutex name     //
    osMutexPrioInherit, // attr_bits                 //
    NULL,               // memory for control block       //
    0U                  // size for control block        //
};

#if USE_AD7606
static volatile uint8_t g_ad7606_started = 0;
static uint16_t g_ad7606_raw[8];
static float g_aux4_sum_v[AD_AUX4_COUNT];
static float g_aux4_sum2_v[AD_AUX4_COUNT];
static uint32_t g_aux4_count = 0U;
static uint32_t g_aux4_count2 = 0U;
#endif

/* USER CODE END PV */

void SystemClock_Config(void);
static void MPU_Config(void);
void MX_FREERTOS_Init(void);

/* USER CODE BEGIN 0 */

#if USE_AD7606
static const float s_aux4_range_lo[AD_AUX4_COUNT] = {20.0f, 18.0f, 8.0f, 20.0f};
static const float s_aux4_range_hi[AD_AUX4_COUNT] = {125.0f, 115.0f, 98.0f, 8000.0f};
static const float s_aux4_defaults[AD_AUX4_COUNT] = {67.8480f, 55.7832f, 49.2850f, 3016.0754f};

static float AD7606_Aux4Clamp(float value, float lo, float hi)
{
  if (value < lo)
  {
    return lo;
  }
  if (value > hi)
  {
    return hi;
  }
  return value;
}

static float AD7606_Aux4DecodeFromAnalogV(uint32_t aux_idx, float analog_v)
{
  float v = AD7606_Aux4Clamp(analog_v, 0.5f, 4.5f);
  float t = (v - 0.5f) / 4.0f;
  if (aux_idx >= AD_AUX4_COUNT)
  {
    return 0.0f;
  }
  return s_aux4_range_lo[aux_idx] + (t * (s_aux4_range_hi[aux_idx] - s_aux4_range_lo[aux_idx]));
}

static void AD7606_Aux4SetDefaults(float dst[AD_AUX4_COUNT])
{
  for (uint32_t i = 0U; i < AD_AUX4_COUNT; ++i)
  {
    dst[i] = s_aux4_defaults[i];
  }
}

static void AD7606_Aux4ResetAccum(float sum_v[AD_AUX4_COUNT], uint32_t *count)
{
  for (uint32_t i = 0U; i < AD_AUX4_COUNT; ++i)
  {
    sum_v[i] = 0.0f;
  }
  if (count != NULL)
  {
    *count = 0U;
  }
}

static void AD7606_Aux4AddSample(float sum_v[AD_AUX4_COUNT], uint32_t *count)
{
  for (uint32_t i = 0U; i < AD_AUX4_COUNT; ++i)
  {
    float analog_v = AD7606_RawToVoltsF(g_ad7606_raw[4U + i]);
    AD7606_DebugVolts[4U + i] = analog_v;
    AD7606_Aux4Values[i] = AD7606_Aux4DecodeFromAnalogV(i, analog_v);
    sum_v[i] += analog_v;
  }
  if (count != NULL)
  {
    (*count)++;
  }
}

static uint8_t AD7606_Aux4PublishMean(float dst[AD_AUX4_COUNT],
                                      const float sum_v[AD_AUX4_COUNT],
                                      uint32_t count)
{
  uint8_t valid_mask = 0U;

  if (count == 0U)
  {
    AD7606_Aux4SetDefaults(dst);
    AD7606_Aux4ValidMask = 0U;
    return 0U;
  }

  for (uint32_t i = 0U; i < AD_AUX4_COUNT; ++i)
  {
    float mean_v = sum_v[i] / (float)count;
    AD7606_DebugVolts[4U + i] = mean_v;
    if ((mean_v < 0.25f) || (mean_v > 4.75f))
    {
      dst[i] = s_aux4_defaults[i];
    }
    else
    {
      dst[i] = AD7606_Aux4DecodeFromAnalogV(i, mean_v);
      valid_mask |= (uint8_t)(1U << i);
    }
    AD7606_Aux4Values[i] = dst[i];
  }

  AD7606_Aux4ValidMask = valid_mask;
  return valid_mask;
}
#endif

/* USER CODE END 0 */

int main(void)
{

  /* MPU Configuration--------------------------------------------------------*/
  MPU_Config();

  /* Enable the CPU Cache */

  /* Enable I-Cache---------------------------------------------------------*/
  SCB_EnableICache();

  /* Enable D-Cache---------------------------------------------------------*/
  SCB_EnableDCache();

  /* MCU Configuration--------------------------------------------------------*/

  /* Reset of all peripherals, Initializes the Flash interface and the Systick. */
  HAL_Init();

  /* Configure the system clock */
  SystemClock_Config();

  /* Initialize all configured peripherals */
  MX_GPIO_Init();
  MX_MDMA_Init();
  MX_DMA_Init();
  MX_USART1_UART_Init();
  MX_FMC_Init();
  MX_DMA2D_Init();
  MX_LTDC_Init();
  MX_TIM3_Init();
  MX_SDMMC1_SD_Init();
  MX_FATFS_Init();
  MX_RTC_Init();
  MX_TIM16_Init();
  MX_QUADSPI_Init();
  MX_TIM2_Init();
  MX_SPI2_Init();
  /* USER CODE BEGIN 2 */
  //		Stack_Size      EQU     0x00000400 //
  //		Stack_Size      EQU     0x0000FF00

  LED_Init();                              //
  SDRAM_Initialization_Sequence(&hsdram1); //
  LCD_RGB_Init();                          //
  Touch_Init();                            //

#if USE_AD7606
  AD7606_Init();
  g_ad7606_started = 0;
  AD7606_Aux4SetDefaults(ADSA_AUX4);
  AD7606_Aux4SetDefaults(ADSA_AUX4_2);
  ADSA_AUX4_valid_mask = 0U;
  ADSA_AUX4_2_valid_mask = 0U;
  AD7606_Aux4ValidMask = 0U;
  AD7606_Aux4ResetAccum(g_aux4_sum_v, &g_aux4_count);
  AD7606_Aux4ResetAccum(g_aux4_sum2_v, &g_aux4_count2);
#endif
  HAL_TIM_Base_Start_IT(&htim2);

  printf("System Start...\r\n");

  //  FreeRTOS
  /* USER CODE END 2 */

  /* Init scheduler */
  osKernelInitialize();  /* Call init function for freertos objects (in cmsis_os2.c) */
  MX_FREERTOS_Init();

  /* Start scheduler */
  osKernelStart();

  /* We should never get here as control is now taken by the scheduler */

  /* Infinite loop */
  while (1)
  {

  }
}

void SystemClock_Config(void)
{
  RCC_OscInitTypeDef RCC_OscInitStruct = {0};
  RCC_ClkInitTypeDef RCC_ClkInitStruct = {0};

  /** Supply configuration update enable
  */
  HAL_PWREx_ConfigSupply(PWR_LDO_SUPPLY);

  /** Configure the main internal regulator output voltage
  */
  __HAL_PWR_VOLTAGESCALING_CONFIG(PWR_REGULATOR_VOLTAGE_SCALE0);

  while(!__HAL_PWR_GET_FLAG(PWR_FLAG_VOSRDY)) {}

  /** Configure LSE Drive Capability
  */
  HAL_PWR_EnableBkUpAccess();
  __HAL_RCC_LSEDRIVE_CONFIG(RCC_LSEDRIVE_LOW);

  /** Initializes the RCC Oscillators according to the specified parameters
  * in the RCC_OscInitTypeDef structure.
  */
  RCC_OscInitStruct.OscillatorType = RCC_OSCILLATORTYPE_HSE|RCC_OSCILLATORTYPE_LSE;
  RCC_OscInitStruct.HSEState = RCC_HSE_ON;
  RCC_OscInitStruct.LSEState = RCC_LSE_ON;
  RCC_OscInitStruct.PLL.PLLState = RCC_PLL_ON;
  RCC_OscInitStruct.PLL.PLLSource = RCC_PLLSOURCE_HSE;
  RCC_OscInitStruct.PLL.PLLM = 5;
  RCC_OscInitStruct.PLL.PLLN = 192;
  RCC_OscInitStruct.PLL.PLLP = 2;
  RCC_OscInitStruct.PLL.PLLQ = 4;
  RCC_OscInitStruct.PLL.PLLR = 2;
  RCC_OscInitStruct.PLL.PLLRGE = RCC_PLL1VCIRANGE_2;
  RCC_OscInitStruct.PLL.PLLVCOSEL = RCC_PLL1VCOWIDE;
  RCC_OscInitStruct.PLL.PLLFRACN = 0;
  if (HAL_RCC_OscConfig(&RCC_OscInitStruct) != HAL_OK)
  {
    Error_Handler();
  }

  /** Initializes the CPU, AHB and APB buses clocks
  */
  RCC_ClkInitStruct.ClockType = RCC_CLOCKTYPE_HCLK|RCC_CLOCKTYPE_SYSCLK
                              |RCC_CLOCKTYPE_PCLK1|RCC_CLOCKTYPE_PCLK2
                              |RCC_CLOCKTYPE_D3PCLK1|RCC_CLOCKTYPE_D1PCLK1;
  RCC_ClkInitStruct.SYSCLKSource = RCC_SYSCLKSOURCE_PLLCLK;
  RCC_ClkInitStruct.SYSCLKDivider = RCC_SYSCLK_DIV1;
  RCC_ClkInitStruct.AHBCLKDivider = RCC_HCLK_DIV2;
  RCC_ClkInitStruct.APB3CLKDivider = RCC_APB3_DIV2;
  RCC_ClkInitStruct.APB1CLKDivider = RCC_APB1_DIV2;
  RCC_ClkInitStruct.APB2CLKDivider = RCC_APB2_DIV2;
  RCC_ClkInitStruct.APB4CLKDivider = RCC_APB4_DIV2;

  if (HAL_RCC_ClockConfig(&RCC_ClkInitStruct, FLASH_LATENCY_4) != HAL_OK)
  {
    Error_Handler();
  }
}

 /* MPU Configuration */

void MPU_Config(void)
{
  MPU_Region_InitTypeDef MPU_InitStruct = {0};

  /* Disables the MPU */
  HAL_MPU_Disable();

  /** Initializes and configures the Region and the memory to be protected
  */
  MPU_InitStruct.Enable = MPU_REGION_ENABLE;
  MPU_InitStruct.Number = MPU_REGION_NUMBER0;
  MPU_InitStruct.BaseAddress = 0xC0000000;
  MPU_InitStruct.Size = MPU_REGION_SIZE_16MB;
  MPU_InitStruct.SubRegionDisable = 0x0;
  MPU_InitStruct.TypeExtField = MPU_TEX_LEVEL0;
  MPU_InitStruct.AccessPermission = MPU_REGION_FULL_ACCESS;
  MPU_InitStruct.DisableExec = MPU_INSTRUCTION_ACCESS_ENABLE;
  MPU_InitStruct.IsShareable = MPU_ACCESS_NOT_SHAREABLE;
  MPU_InitStruct.IsCacheable = MPU_ACCESS_CACHEABLE;
  MPU_InitStruct.IsBufferable = MPU_ACCESS_NOT_BUFFERABLE;

  HAL_MPU_ConfigRegion(&MPU_InitStruct);

  /** Initializes and configures the Region and the memory to be protected
  */
  MPU_InitStruct.Number = MPU_REGION_NUMBER1;
  MPU_InitStruct.BaseAddress = 0x24000000;
  MPU_InitStruct.Size = MPU_REGION_SIZE_512KB;
  MPU_InitStruct.TypeExtField = MPU_TEX_LEVEL1;
  MPU_InitStruct.IsShareable = MPU_ACCESS_SHAREABLE;
  MPU_InitStruct.IsBufferable = MPU_ACCESS_BUFFERABLE;

  HAL_MPU_ConfigRegion(&MPU_InitStruct);
  /* Enables the MPU */
  HAL_MPU_Enable(MPU_PRIVILEGED_DEFAULT);

}

void HAL_TIM_PeriodElapsedCallback(TIM_HandleTypeDef *htim)
{
  if (htim->Instance == TIM17)
  {
    HAL_IncTick();
  }
  /* USER CODE BEGIN Callback 1 */
	if(htim->Instance == TIM3)  //
    {

    }
  if (htim->Instance == TIM2)
  {
#if USE_AD7606
    if (!g_ad7606_started)
    {
      AD7606_StartConv();
      g_ad7606_started = 1;
      return;
    }
    if (READ_AD7606_BUSY)
    {
      g_ad7606_miss++;
      return;
    }

    AD7606_ReadRaw8(g_ad7606_raw);
    AD7606_StartConv(); /* 立即启动下一次转换，缩短空档 */
    g_ad7606_frames++;

    ADS131A04_Buf[0] = AD7606_RawToVoltsF(g_ad7606_raw[0]);
    ADS131A04_Buf[1] = AD7606_RawToVoltsF(g_ad7606_raw[1]);
    ADS131A04_Buf[2] = AD7606_RawToVoltsF(g_ad7606_raw[2]) * 465.95f / 473.20f;
    ADS131A04_Buf[3] = AD7606_RawToVoltsF(g_ad7606_raw[3]);
    for (uint8_t ch = 0; ch < 8U; ch++)
    {
      AD7606_DebugRaw[ch] = g_ad7606_raw[ch];
    }
    for (uint8_t ch = 0; ch < 4U; ch++)
    {
      AD7606_DebugVolts[ch] = ADS131A04_Buf[ch];
    }
    AD7606_DebugBusy = READ_AD7606_BUSY ? 1U : 0U;
    AD7606_DebugDb7 = READ_AD7606_DB7 ? 1U : 0U;

    if (ADS131A04_flag == 0)
    {
      for (uint8_t ch = 0; ch < 4; ch++)
      {
        ADSA_B[ch][number] = ADS131A04_Buf[ch];
      }
      AD7606_Aux4AddSample(g_aux4_sum_v, &g_aux4_count);
      number++;
      if (number == AD_ACQ_POINTS)
      {
        ADSA_AUX4_valid_mask = AD7606_Aux4PublishMean(ADSA_AUX4, g_aux4_sum_v, g_aux4_count);
        AD7606_Aux4ResetAccum(g_aux4_sum_v, &g_aux4_count);
        ADS131A04_flag = 1;
        ADS131A04_flag2 = 0;
        number = 0;
        number2 = 0;
      }
    }
    else if (ADS131A04_flag2 == 0)
    {
      for (uint8_t ch = 0; ch < 4; ch++)
      {
        ADSA_B2[ch][number2] = ADS131A04_Buf[ch];
      }
      AD7606_Aux4AddSample(g_aux4_sum2_v, &g_aux4_count2);
      number2++;
      if (number2 == AD_ACQ_POINTS)
      {
        ADSA_AUX4_2_valid_mask = AD7606_Aux4PublishMean(ADSA_AUX4_2, g_aux4_sum2_v, g_aux4_count2);
        AD7606_Aux4ResetAccum(g_aux4_sum2_v, &g_aux4_count2);
        ADS131A04_flag2 = 2;
        ADS131A04_flag = 0;
        number = 0;
        number2 = 0;
      }
    }
#endif
  }
  /* USER CODE END Callback 1 */
}

void Error_Handler(void)
{
  __disable_irq();
  while (1)
  {
  }
}

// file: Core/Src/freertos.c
/* USER CODE BEGIN Header */
/**
 ******************************************************************************
 * File Name          : freertos.c
 * Description        : Code for freertos applications
 ******************************************************************************
 * @attention
 *
 * Copyright (c) 2024 STMicroelectronics.
 * All rights reserved.
 *
 * This software is licensed under terms that can be found in the LICENSE file
 * in the root directory of this software component.
 * If no LICENSE file comes with this software, it is provided AS-IS.
 *
 ******************************************************************************
 */
/* USER CODE END Header */

#include "FreeRTOS.h"
#include "task.h"
#include "main.h"
#include "cmsis_os.h"

/* USER CODE BEGIN Includes */
#include "led.h"
#include "touch_800x480.h"
#include "tim.h"
#include "stm32h7xx_hal.h"
#include "SD.h"
#include "fatfs.h"
#include "tim.h"

#include "lvgl.h"
#include "lv_port_disp.h"
#include "lv_port_indev.h"
// Demo 已移除，使用自定义 EdgeWind UI
#include "EdgeWind_UI/edgewind_ui.h"
#include "edge_comm.h"
#include "edgewind_buzzer.h"
#include "ESP32SPI/esp32_spi_debug.h"
#include "qspi_w25q256.h"
#include "GUI-Guider_Runtime/gui_assets_sync.h"
#include <string.h>
#include <stdio.h>

/* USER CODE END Includes */

/* USER CODE BEGIN PTD */
void HAL_Delay(uint32_t Delay)
{
  if (Delay == 0U)
  {
    return;
  }

  uint32_t tickstart = HAL_GetTick();

  if ((osKernelGetState() == osKernelRunning) && (__get_IPSR() == 0U))
  {
    while ((HAL_GetTick() - tickstart) < Delay)
    {
      osDelay(1);
    }
    return;
  }

  while ((HAL_GetTick() - tickstart) < Delay)
  {
    /* busy wait before scheduler starts or in ISR */
  }
}
/* USER CODE END PTD */

/* USER CODE BEGIN PM */

#ifndef W25Q256_SELFTEST_ENABLE
/* 默认关闭：避免每次上电都擦写外部 Flash。
 * 需要自检时手动改为 1，或通过编译宏覆盖。
 */
#define W25Q256_SELFTEST_ENABLE 0
#endif

/* 自检等级：
 * 1: 单扇区擦除 + 单页写入 + 读回校验（最快，推荐长期保留）
 * 2: 增加跨页/跨扇区写入读回（更贴近真实存储使用）
 * 3: 预留（可在后续加入 16MB 边界/更大范围测试）
 */
#ifndef W25Q256_SELFTEST_LEVEL
/* 默认自检等级（仅在 W25Q256_SELFTEST_ENABLE=1 时生效） */
#define W25Q256_SELFTEST_LEVEL 2
#endif

/* 内存映射读取校验（可选）：开启后会将 QSPI 切到 memory-mapped 再 memcpy 读回校验。
 * 注意：memory-mapped 与 cache 行为相关，若你担心影响系统其他读写，保持 0 即可。
 */
#ifndef W25Q256_SELFTEST_USE_MEMORY_MAPPED
#define W25Q256_SELFTEST_USE_MEMORY_MAPPED 0
#endif

/* 启动阶段同步资源时，暂时挂起 ESP 任务，避免文件系统/总线竞争 */
#ifndef EW_SUSPEND_ESP_DURING_SYNC
#define EW_SUSPEND_ESP_DURING_SYNC 0
#endif

#ifndef EW_BOOT_QSPI_SYNC_ENABLE
#define EW_BOOT_QSPI_SYNC_ENABLE 1
#endif

#ifndef ESP32_SPI_AUTOTEST_ON_BOOT
#define ESP32_SPI_AUTOTEST_ON_BOOT 0
#endif

#ifndef ESP32_SPI_BOOT_AUTO_FALLBACK_MS
#define ESP32_SPI_BOOT_AUTO_FALLBACK_MS 5000U
#endif

#define W25Q256_SELFTEST_ADDR   (0x1FF0000u) /* 32MB Flash 末尾附近，避开常用数据区 */
#define W25Q256_SELFTEST_LEN    (256u)       /* 单页测试 */
#define W25Q256_CROSS_LEN       (512u)       /* 跨页/跨扇区测试长度 */

static int8_t W25Q256_SelfTest_Small(void)
{
  uint8_t tx[W25Q256_SELFTEST_LEN];
  uint8_t rx[W25Q256_SELFTEST_LEN];
  uint32_t id;
  int8_t ret;

  ret = QSPI_W25Qxx_Init();
  id  = QSPI_W25Qxx_ReadID();
  printf("[W25Q256] init ret=%d, JEDEC=0x%06lX\r\n", (int)ret, (unsigned long)id);
  if (ret != QSPI_W25Qxx_OK)
  {
    return ret;
  }

  ret = QSPI_W25Qxx_SectorErase(W25Q256_SELFTEST_ADDR);
  printf("[W25Q256] sector erase @0x%08lX ret=%d\r\n", (unsigned long)W25Q256_SELFTEST_ADDR, (int)ret);
  if (ret != QSPI_W25Qxx_OK)
  {
    return ret;
  }

  for (uint32_t i = 0; i < W25Q256_SELFTEST_LEN; i++)
  {
    tx[i] = (uint8_t)(i ^ 0xA5u);
    rx[i] = 0;
  }

  ret = QSPI_W25Qxx_WritePage(tx, W25Q256_SELFTEST_ADDR, (uint16_t)W25Q256_SELFTEST_LEN);
  printf("[W25Q256] write page ret=%d\r\n", (int)ret);
  if (ret != QSPI_W25Qxx_OK)
  {
    return ret;
  }

  ret = QSPI_W25Qxx_ReadBuffer(rx, W25Q256_SELFTEST_ADDR, W25Q256_SELFTEST_LEN);
  printf("[W25Q256] read back ret=%d\r\n", (int)ret);
  if (ret != QSPI_W25Qxx_OK)
  {
    return ret;
  }

  if (memcmp(tx, rx, W25Q256_SELFTEST_LEN) != 0)
  {
    for (uint32_t i = 0; i < W25Q256_SELFTEST_LEN; i++)
    {
      if (tx[i] != rx[i])
      {
        printf("[W25Q256] verify FAIL @+%lu tx=0x%02X rx=0x%02X\r\n",
               (unsigned long)i, (unsigned int)tx[i], (unsigned int)rx[i]);
        break;
      }
    }
    return (int8_t)W25Qxx_ERROR_TRANSMIT;
  }

  printf("[W25Q256] selftest PASS (erase+program+readback)\r\n");
  return QSPI_W25Qxx_OK;
}

static int8_t W25Q256_SelfTest_CrossPageAndSector(void)
{
  const uint32_t base0 = W25Q256_SELFTEST_ADDR;          /* 4KB 扇区对齐 */
  const uint32_t base1 = W25Q256_SELFTEST_ADDR + 0x1000; /* 下一个 4KB 扇区 */
  const uint32_t start = base0 + 0x0F80u;                /* 故意靠近扇区末尾，触发跨扇区 */
  const uint32_t len   = W25Q256_CROSS_LEN;              /* 512B：跨页且跨扇区 */

  uint8_t tx[W25Q256_CROSS_LEN];
  uint8_t rx[W25Q256_CROSS_LEN];

  printf("[W25Q256] cross-sector test: erase 2 sectors, start=0x%08lX len=%lu\r\n",
         (unsigned long)start, (unsigned long)len);

  int8_t ret = QSPI_W25Qxx_SectorErase(base0);
  printf("[W25Q256] erase sector0 @0x%08lX ret=%d\r\n", (unsigned long)base0, (int)ret);
  if (ret != QSPI_W25Qxx_OK) return ret;

  ret = QSPI_W25Qxx_SectorErase(base1);
  printf("[W25Q256] erase sector1 @0x%08lX ret=%d\r\n", (unsigned long)base1, (int)ret);
  if (ret != QSPI_W25Qxx_OK) return ret;

  /* 擦除校验：读少量数据确认为 0xFF */
  {
    uint8_t blank[64];
    ret = QSPI_W25Qxx_ReadBuffer(blank, base0, sizeof(blank));
    if (ret != QSPI_W25Qxx_OK) return ret;
    for (uint32_t i = 0; i < sizeof(blank); i++)
    {
      if (blank[i] != 0xFFu)
      {
        printf("[W25Q256] erase verify FAIL sector0 @+%lu =0x%02X\r\n",
               (unsigned long)i, (unsigned int)blank[i]);
        return (int8_t)W25Qxx_ERROR_Erase;
      }
    }

    ret = QSPI_W25Qxx_ReadBuffer(blank, base1, sizeof(blank));
    if (ret != QSPI_W25Qxx_OK) return ret;
    for (uint32_t i = 0; i < sizeof(blank); i++)
    {
      if (blank[i] != 0xFFu)
      {
        printf("[W25Q256] erase verify FAIL sector1 @+%lu =0x%02X\r\n",
               (unsigned long)i, (unsigned int)blank[i]);
        return (int8_t)W25Qxx_ERROR_Erase;
      }
    }
    printf("[W25Q256] erase verify PASS (both sectors blank)\r\n");
  }

  for (uint32_t i = 0; i < len; i++)
  {
    tx[i] = (uint8_t)((i * 37u) ^ 0x5Au);
    rx[i] = 0;
  }

  ret = QSPI_W25Qxx_WriteBuffer(tx, start, len);
  printf("[W25Q256] write buffer (cross) ret=%d\r\n", (int)ret);
  if (ret != QSPI_W25Qxx_OK) return ret;

  ret = QSPI_W25Qxx_ReadBuffer(rx, start, len);
  printf("[W25Q256] read buffer (cross) ret=%d\r\n", (int)ret);
  if (ret != QSPI_W25Qxx_OK) return ret;

  if (memcmp(tx, rx, len) != 0)
  {
    for (uint32_t i = 0; i < len; i++)
    {
      if (tx[i] != rx[i])
      {
        printf("[W25Q256] cross verify FAIL @+%lu tx=0x%02X rx=0x%02X\r\n",
               (unsigned long)i, (unsigned int)tx[i], (unsigned int)rx[i]);
        break;
      }
    }
    return (int8_t)W25Qxx_ERROR_TRANSMIT;
  }

#if W25Q256_SELFTEST_USE_MEMORY_MAPPED
  ret = QSPI_W25Qxx_MemoryMappedMode();
  printf("[W25Q256] enter memory-mapped ret=%d\r\n", (int)ret);
  if (ret == QSPI_W25Qxx_OK)
  {
    uint8_t mm[W25Q256_CROSS_LEN];
    memcpy(mm, (uint8_t *)0x90000000u + start, len);
    if (memcmp(tx, mm, len) != 0)
    {
      printf("[W25Q256] memory-mapped verify FAIL\r\n");
      return (int8_t)W25Qxx_ERROR_TRANSMIT;
    }
    printf("[W25Q256] memory-mapped verify PASS\r\n");
  }
#endif

  printf("[W25Q256] cross-sector test PASS\r\n");
  return QSPI_W25Qxx_OK;
}

/* USER CODE END PM */

/* Definitions for LVGL940 */
osThreadId_t LVGL940Handle;
const osThreadAttr_t LVGL940_attributes = {
  .name = "LVGL940",
  .stack_size = 2048 * 4,
  .priority = (osPriority_t) osPriorityNormal,
};
/* Definitions for LED */
osThreadId_t LEDHandle;
const osThreadAttr_t LED_attributes = {
  .name = "LED",
  .stack_size = 128 * 4,
  .priority = (osPriority_t) osPriorityLow,
};
/* Definitions for Main */
osThreadId_t MainHandle;
const osThreadAttr_t Main_attributes = {
  .name = "Main",
  .stack_size = 8192 * 4,
  .priority = (osPriority_t) osPriorityLow,
};
/* Definitions for EdgeComm */
osThreadId_t EdgeCommHandle;
const osThreadAttr_t EdgeComm_attributes = {
  .name = "EdgeComm",
  .stack_size = 5128 * 4,
  .priority = (osPriority_t) osPriorityAboveNormal,
};
/* Definitions for DSPAlgo */
osThreadId_t DSPAlgoHandle;
const osThreadAttr_t DSPAlgo_attributes = {
  .name = "DSPAlgo",
  .stack_size = 3072 * 4,
  /* 低于 LVGL(Normal)：UI 每 11ms 刷新可立即抢占 DSP 的 FFT/AI 计算突发，
     消除每秒约 4 次的周期性卡顿。DSP 消费的是 DMA 已就绪的采集窗口，
     降优先级只是把计算穿插到 UI 空隙，不丢窗口、不改 250ms 推理节奏。 */
  .priority = (osPriority_t) osPriorityBelowNormal,
};
/* Definitions for Upload */
osThreadId_t UploadHandle;
const osThreadAttr_t Upload_attributes = {
  .name = "Upload",
  .stack_size = 3072 * 4,
  .priority = (osPriority_t) osPriorityBelowNormal,
};

/* USER CODE BEGIN FunctionPrototypes */
extern const osMutexAttr_t Thread_Mutex_attr;
void ESP32_SPI_TestTask(void *argument);

/* USER CODE END FunctionPrototypes */

void LVGL_Task(void *argument);
void LED_Task(void *argument);
void Main_Task(void *argument);
void EdgeComm_Task(void *argument);
void DSP_Algorithm_Task(void *argument);
void Upload_Task(void *argument);

void MX_FREERTOS_Init(void); /* (MISRA C 2004 rule 8.1) */

/* Hook prototypes */
void vApplicationTickHook(void);

/* USER CODE BEGIN 3 */
void vApplicationTickHook(void)
{
  /* This function will be called by each tick interrupt if
  configUSE_TICK_HOOK is set to 1 in FreeRTOSConfig.h. User code can be
  added here, but the tick hook is called from an interrupt context, so
  code must not attempt to block, and only the interrupt safe FreeRTOS API
  functions can be used (those that end in FromISR()). */

  lv_tick_inc(1);
}
/* USER CODE END 3 */

void MX_FREERTOS_Init(void) {
  /* USER CODE BEGIN Init */
  EdgeWind_Buzzer_Init();

  /* USER CODE END Init */

  /* USER CODE BEGIN RTOS_MUTEX */
  /* add mutexes, ... */
  mutex_id = osMutexNew(&Thread_Mutex_attr);
  /* USER CODE END RTOS_MUTEX */

  /* Create the thread(s) */
  /* creation of LVGL940 */
  LVGL940Handle = osThreadNew(LVGL_Task, NULL, &LVGL940_attributes);

  /* creation of LED */
  LEDHandle = osThreadNew(LED_Task, NULL, &LED_attributes);

  /* creation of Main */
  MainHandle = osThreadNew(Main_Task, NULL, &Main_attributes);

  /* creation of EdgeComm */
  EdgeCommHandle = osThreadNew(EdgeComm_Task, NULL, &EdgeComm_attributes);

  /* creation of DSPAlgo */
  DSPAlgoHandle = osThreadNew(DSP_Algorithm_Task, NULL, &DSPAlgo_attributes);

  /* creation of Upload */
  UploadHandle = osThreadNew(Upload_Task, NULL, &Upload_attributes);

  /* USER CODE BEGIN RTOS_THREADS */
  static const osThreadAttr_t Buzzer_attributes = {
    .name = "Buzzer",
    .stack_size = 512 * 4,
    .priority = (osPriority_t) osPriorityAboveNormal,
  };
  (void)osThreadNew(EdgeWind_Buzzer_Task, NULL, &Buzzer_attributes);

#if ESP32_SPI_AUTOTEST_ON_BOOT
  static const osThreadAttr_t ESP32_SPI_Test_attributes = {
    .name = "ESP32SPITest",
    .stack_size = 4096 * 4,
    .priority = (osPriority_t) osPriorityLow,
  };
  osThreadNew(ESP32_SPI_TestTask, NULL, &ESP32_SPI_Test_attributes);
#endif
  /* USER CODE END RTOS_THREADS */

}

void LVGL_Task(void *argument)
{
  /* USER CODE BEGIN LVGL_Task */
  uint32_t time;
  UBaseType_t min_hw = (UBaseType_t)0xFFFFFFFFu;
  TickType_t last_log = 0;
  //  // LVGL图形库初始化三件套
  lv_init();            // 初始化LVGL核心库（内存管理、内部变量等）
  lv_port_disp_init();  // 初始化显示驱动接口（配置帧缓冲区、注册刷新回调）
  lv_port_indev_init(); // 初始化输入设备接口（注册触摸屏/编码器驱动）

  /* 初始化 EdgeWind 自定义 UI */
  edgewind_ui_init();
  /* Infinite loop */
  for(;;)
  {

    /* === 临界区开始（保护LVGL操作）=== */
    osMutexAcquire(mutex_id, osWaitForever);

    /* EdgeWind UI 数据刷新 */
    edgewind_ui_refresh();

    /* LVGL 核心处理 */
    lv_task_handler();

    osMutexRelease(mutex_id);
    /* === 临界区结束 === */

    /* 低频监测 LVGL 线程栈水位（观察是否逼近溢出） */
    TickType_t now = xTaskGetTickCount();
    if ((now - last_log) > pdMS_TO_TICKS(2000)) {
      UBaseType_t hw = uxTaskGetStackHighWaterMark(NULL);
      if (hw < min_hw) {
        min_hw = hw;
        printf("[LVGL] stack HW=%lu words, freeHeap=%lu\r\n",
               (unsigned long)hw,
               (unsigned long)xPortGetFreeHeapSize());
      }
      last_log = now;
    }

    //    /* 周期延时（关键性能参数）*/
    osDelay(LV_DEF_REFR_PERIOD + 1); // 保持屏幕刷新率稳定（典型值30ms≈33FPS）

    // 注意：
    // 1. 延时过短：导致刷新不全（屏幕闪烁）
    // 2. 延时过长：界面响应迟滞
    // 3. LV_DISP_DEF_REFR_PERIOD应与屏显参数匹配（在lv_conf.h中配置）

    // 调试语句（使用时需注意串口输出可能影响实时性）
    // printf("GUI task heartbeat\r\n");
  }
  /* USER CODE END LVGL_Task */
}

void LED_Task(void *argument)
{
  /* USER CODE BEGIN LED_Task */
  LED_Mode_t mode = LED_MODE_NORMAL;
  uint32_t delay_ms = 500;

  /* Infinite loop */
  for(;;)
  {
    mode = LED_GetMode();

    switch(mode) {
        case LED_MODE_NORMAL:    // Normal: 1Hz slow blink
            delay_ms = 500;
            LED1_Toggle;
            break;
        case LED_MODE_WARNING:   // Warning: 2Hz fast blink
            delay_ms = 250;
            LED1_Toggle;
            break;
        case LED_MODE_CRITICAL:  // Critical: 4Hz rapid blink
            delay_ms = 125;
            LED1_Toggle;
            break;
        case LED_MODE_EMERGENCY: // Emergency: constant on
            LED1_ON;
            delay_ms = 1000;
            break;
        default:
            delay_ms = 500;
            LED1_Toggle;
            break;
    }

    osDelay(delay_ms);
  }
  /* USER CODE END LED_Task */
}

void Main_Task(void *argument)
{
  /* USER CODE BEGIN Main_Task */

#if EW_BOOT_QSPI_SYNC_ENABLE
#if (EW_SUSPEND_ESP_DURING_SYNC != 0)
  if (EdgeCommHandle) {
    osThreadSuspend(EdgeCommHandle);
    printf("[QSPI_FS] suspended ESP task during sync\r\n");
  }
#endif

  if (mutex_id) {
    osMutexAcquire(mutex_id, osWaitForever);
    printf("[QSPI_FS] locked LVGL mutex during sync\r\n");
  }

#if W25Q256_SELFTEST_ENABLE
  osDelay(200); /* 让系统先跑起来，避免和启动阶段串口输出打架 */
  (void)W25Q256_SelfTest_Small();
#if (W25Q256_SELFTEST_LEVEL >= 2)
  (void)W25Q256_SelfTest_CrossPageAndSector();
#endif
#endif

  uint32_t t0 = HAL_GetTick();
  FRESULT fr_qspi = QSPIFS_MountOrMkfs();
  uint32_t t1 = HAL_GetTick();
  printf("[QSPI_FS] QSPIFS_MountOrMkfs=%d, dt=%lu ms\r\n", (int)fr_qspi, (unsigned long)(t1 - t0));

  FRESULT fr_sync = GUI_Assets_SyncFromSD();
  uint32_t t2 = HAL_GetTick();
  printf("[QSPI_FS] GUI_Assets_SyncFromSD=%d, dt=%lu ms\r\n", (int)fr_sync, (unsigned long)(t2 - t1));
  printf("[QSPI_FS] Main stack HW=%lu words, freeHeap=%lu bytes\r\n",
         (unsigned long)uxTaskGetStackHighWaterMark(NULL),
         (unsigned long)xPortGetFreeHeapSize());

  if (mutex_id) {
    osMutexRelease(mutex_id);
    printf("[QSPI_FS] unlocked LVGL mutex\r\n");
  }

#if (EW_SUSPEND_ESP_DURING_SYNC != 0)
  if (EdgeCommHandle) {
    osThreadResume(EdgeCommHandle);
    printf("[QSPI_FS] resumed ESP task\r\n");
  }
#endif
#else
  printf("[QSPI_FS] boot sync skipped\r\n");
#endif

  /* Infinite loop */
  for(;;)
  {
    osDelay(1);
  }
  /* USER CODE END Main_Task */
}

void EdgeComm_Task(void *argument)
{
  /* USER CODE BEGIN EdgeComm_Task */
  osThreadId_t self = osThreadGetId();
  if (self)
  {
    osThreadSetPriority(self, osPriorityAboveNormal);
  }
  ESP_Console_Init();
  /* 不再开机自启动连接：由 DeviceConnect 界面按钮驱动 */
  ESP_UI_TaskInit();
  if (self)
  {
    osThreadSetPriority(self, osPriorityNormal);
  }
  uint8_t boot_autoreconnect_checked = 0;
  uint32_t boot_autoreconnect_start = HAL_GetTick();
  uint32_t boot_autoreconnect_next = boot_autoreconnect_start + 3000U;
  /* Infinite loop */
  for(;;)
  {
    ESP_UI_TaskPoll();
    ESP_Console_Poll();
    if (!boot_autoreconnect_checked)
    {
      uint32_t now = HAL_GetTick();
      if ((int32_t)(now - boot_autoreconnect_next) >= 0)
      {
        bool auto_reconnect_en = false;
        bool last_reporting = false;
        boot_autoreconnect_next = now + 1000U;
        bool sd_runtime_ok = ESP_Config_LoadRuntimeFromSD();
        if (ESP_AutoReconnect_Read(&auto_reconnect_en, &last_reporting))
        {
          boot_autoreconnect_checked = 1U;
          printf("[ESP_BOOT] autoreconnect cfg: enabled=%u last_reporting=%u\r\n",
                 auto_reconnect_en ? 1U : 0U,
                 last_reporting ? 1U : 0U);
          if (auto_reconnect_en && last_reporting && sd_runtime_ok)
          {
            printf("[ESP_BOOT] queue AUTO connect/report from SD flag\r\n");
            (void)ESP_UI_SendCmd(ESP_UI_CMD_AUTO_CONNECT);
          }
          else if (auto_reconnect_en && last_reporting && !sd_runtime_ok)
          {
            printf("[ESP_BOOT] autoreconnect skipped: SD runtime config invalid\r\n");
          }
        }
        else if (sd_runtime_ok && ((now - boot_autoreconnect_start) > ESP32_SPI_BOOT_AUTO_FALLBACK_MS))
        {
          boot_autoreconnect_checked = 1U;
          printf("[ESP_BOOT] autoreconnect cfg unavailable, fallback AUTO from SD runtime\r\n");
          (void)ESP_UI_SendCmd(ESP_UI_CMD_AUTO_CONNECT);
        }
        else if ((now - boot_autoreconnect_start) > 30000U)
        {
          boot_autoreconnect_checked = 1U;
          printf("[ESP_BOOT] autoreconnect cfg unavailable, skip boot auto\r\n");
        }
      }
    }
    /* EdgeComm task now handles only UI/console/control.
       DSP and upload run in independent producer/consumer tasks. */
    osDelay(5);
  }
  /* USER CODE END EdgeComm_Task */
}

void DSP_Algorithm_Task(void *argument)
{
  /* USER CODE BEGIN DSP_Algorithm_Task */
  (void)argument;
  /* High-priority local path: consume completed acquisition windows,
     compute FFT/fault features, and publish latest upload snapshots. */
  for (;;)
  {
    ESP_Update_Data_And_FFT();
    osDelay(1);
  }
  /* USER CODE END DSP_Algorithm_Task */
}

void Upload_Task(void *argument)
{
  /* USER CODE BEGIN Upload_Task */
  (void)argument;
  /* Low-priority consumer: upload only the latest processed snapshot.
     If ESP32/cloud is busy, DSP keeps running and old upload snapshots are dropped. */
  for (;;)
  {
    if (ESP_UI_IsReporting())
    {
      if (ESP_ServerReportFull())
      {
        ESP_Post_Data();
      }
      else
      {
        ESP_Post_Summary();
      }
    }
    osDelay(2);
  }
  /* USER CODE END Upload_Task */
}

/* USER CODE BEGIN Application */
void ESP32_SPI_TestTask(void *argument)
{
  (void)argument;
  osDelay(10000);
  ESP32_SPI_DebugRunPing();
  osThreadTerminate(osThreadGetId());
  for (;;) {
    osDelay(osWaitForever);
  }
}

/* USER CODE END Application */
